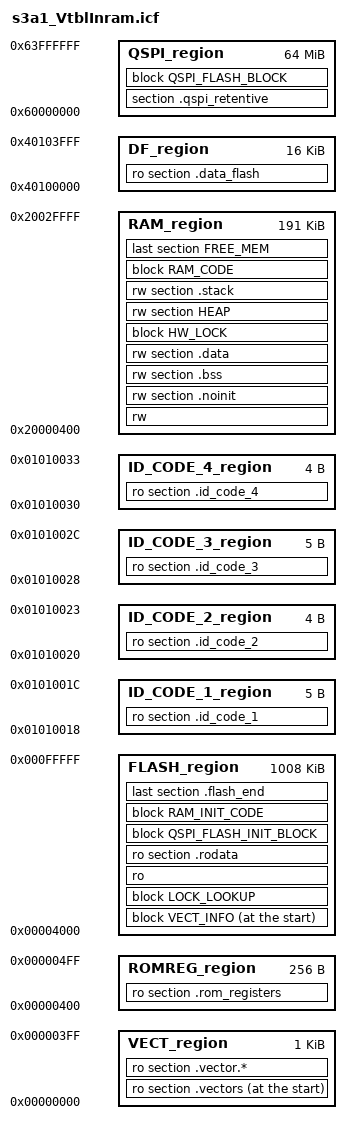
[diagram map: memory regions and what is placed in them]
/* Revision History
   v1.00 - First version. Factory Flash is temporarily located in 2nd 8KB block
   v1.10 - Added SDRAM section
   v1.20 - Added QSPI section, section name cleanup
   v1.30 - Added qspi_flash_init section in FLASH
*/

/*-Memory Regions-*/
/* This linker script puts the vector table in RAM for the swap blocks test */
define symbol region_VECT_start    = 0x00000000;
define symbol region_VECT_end      = 0x000003FF;
define symbol region_ROMREG_start  = 0x00000400;
define symbol region_ROMREG_end    = 0x000004FF;

/* We're testing swap block functionality so we want to load the app code safely above the swap block area */
define symbol region_FLASH_start   = 0x00004000;
define symbol region_FLASH_end     = 0x000FFFFF;


/* We've already put the vector table at the very start of RAM, so 'real' RAM starts here */
define symbol region_RAM_start     = 0x20000400;
define symbol region_RAM_end       = 0x2002FFFF;
define symbol region_DF_start      = 0x40100000;
define symbol region_DF_end        = 0x40103FFF;
define symbol region_QSPI_start    = 0x60000000;
define symbol region_QSPI_end      = 0x63FFFFFF;

define symbol region_ID_CODE_1_start    = 0x01010018;
define symbol region_ID_CODE_1_end      = 0x0101001C;
define symbol region_ID_CODE_2_start    = 0x01010020;
define symbol region_ID_CODE_2_end      = 0x01010023;
define symbol region_ID_CODE_3_start    = 0x01010028;
define symbol region_ID_CODE_3_end      = 0x0101002C;
define symbol region_ID_CODE_4_start    = 0x01010030;
define symbol region_ID_CODE_4_end      = 0x01010033;


/* Stack and heap sizes are defined in bsp_cfg.h */

define memory mem with size     = 4G;
define region VECT_region       = mem:[from region_VECT_start   to region_VECT_end];
define region ROMREG_region     = mem:[from region_ROMREG_start to region_ROMREG_end];
define region FLASH_region      = mem:[from region_FLASH_start  to region_FLASH_end];
define region RAM_region        = mem:[from region_RAM_start    to region_RAM_end];
define region DF_region         = mem:[from region_DF_start     to region_DF_end];
define region QSPI_region       = mem:[from region_QSPI_start   to region_QSPI_end];

define region ID_CODE_1_region  = mem:[from region_ID_CODE_1_start   to region_ID_CODE_1_end];
define region ID_CODE_2_region  = mem:[from region_ID_CODE_2_start   to region_ID_CODE_2_end];
define region ID_CODE_3_region  = mem:[from region_ID_CODE_3_start   to region_ID_CODE_3_end];
define region ID_CODE_4_region  = mem:[from region_ID_CODE_4_start   to region_ID_CODE_4_end];

initialize manually { readwrite };
initialize manually { section .qspi_flash };
do not initialize   { section .qspi_retentive };
do not initialize   { zeroinit };
initialize manually { section .code_in_ram };
/* Main thread local storage */
initialize manually { section __DLIB_PERTHREAD };

define block RAM_INIT_CODE   { section .code_in_ram_init };
define block RAM_CODE        { section .code_in_ram };

define block QSPI_FLASH_INIT_BLOCK { section .qspi_flash_init };
define block QSPI_FLASH_BLOCK      { section .qspi_flash };
define block VECT_INFO                     { ro section .vector_info.* };
keep                                       { section .vector*};
define block LOCK_LOOKUP                   { ro section .hw_lock_lookup.* };
keep                                       { section .hw_lock_lookup*};
define block HW_LOCK with alignment=1      { rw section .hw_lock.* };
keep                                       { section .hw_lock*};

place at start of VECT_region  { ro section .vectors };
place in VECT_region           { ro section .vector.* };
place in ROMREG_region         { ro section .rom_registers };
place at start of FLASH_region { block VECT_INFO };
place in FLASH_region   { block LOCK_LOOKUP,
                          ro,
                          ro section .rodata,
                          block QSPI_FLASH_INIT_BLOCK,
                          block RAM_INIT_CODE, 
                          last section .flash_end };
keep {section .flash_end};
place in RAM_region     { rw,
                          rw section .noinit,
                          rw section .bss,
                          rw section .data,
                          block HW_LOCK,
                          rw section HEAP,
                          rw section .stack,
                          block RAM_CODE };
place in DF_region      { ro section .data_flash };
place in QSPI_region    { section .qspi_retentive };
place in QSPI_region    { block QSPI_FLASH_BLOCK };
place in RAM_region     { last section FREE_MEM};

place in ID_CODE_1_region  { ro section .id_code_1 };
place in ID_CODE_2_region  { ro section .id_code_2 };
place in ID_CODE_3_region  { ro section .id_code_3 };
place in ID_CODE_4_region  { ro section .id_code_4 };

define exported symbol __qspi_region_max_size__ = size(QSPI_region);
define exported symbol __qspi_region_start_address__ = region_QSPI_start;
define exported symbol __qspi_region_end_address__ = region_QSPI_end;

define exported symbol __ROM_Start = region_FLASH_start;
